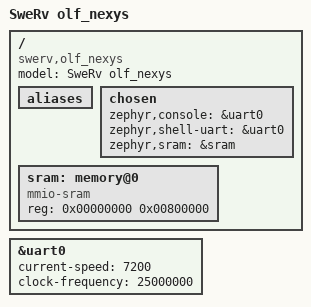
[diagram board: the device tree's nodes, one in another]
/* SPDX-License-Identifier: Apache-2.0 */

/dts-v1/;

#include <riscv32-swerv.dtsi>

/ {
	model = "SweRv olf_nexys";
	compatible = "swerv,olf_nexys";
	aliases {
	};

	chosen {
		zephyr,console = &uart0;
		zephyr,shell-uart = &uart0;
		zephyr,sram = &sram;
	};

	sram: memory@0 {
		compatible = "mmio-sram";
		reg = <0x00000000 0x00800000>;
	};
};


&uart0 {
	status = "ok";
	current-speed = <7200>;
	clock-frequency = <25000000>;
};

